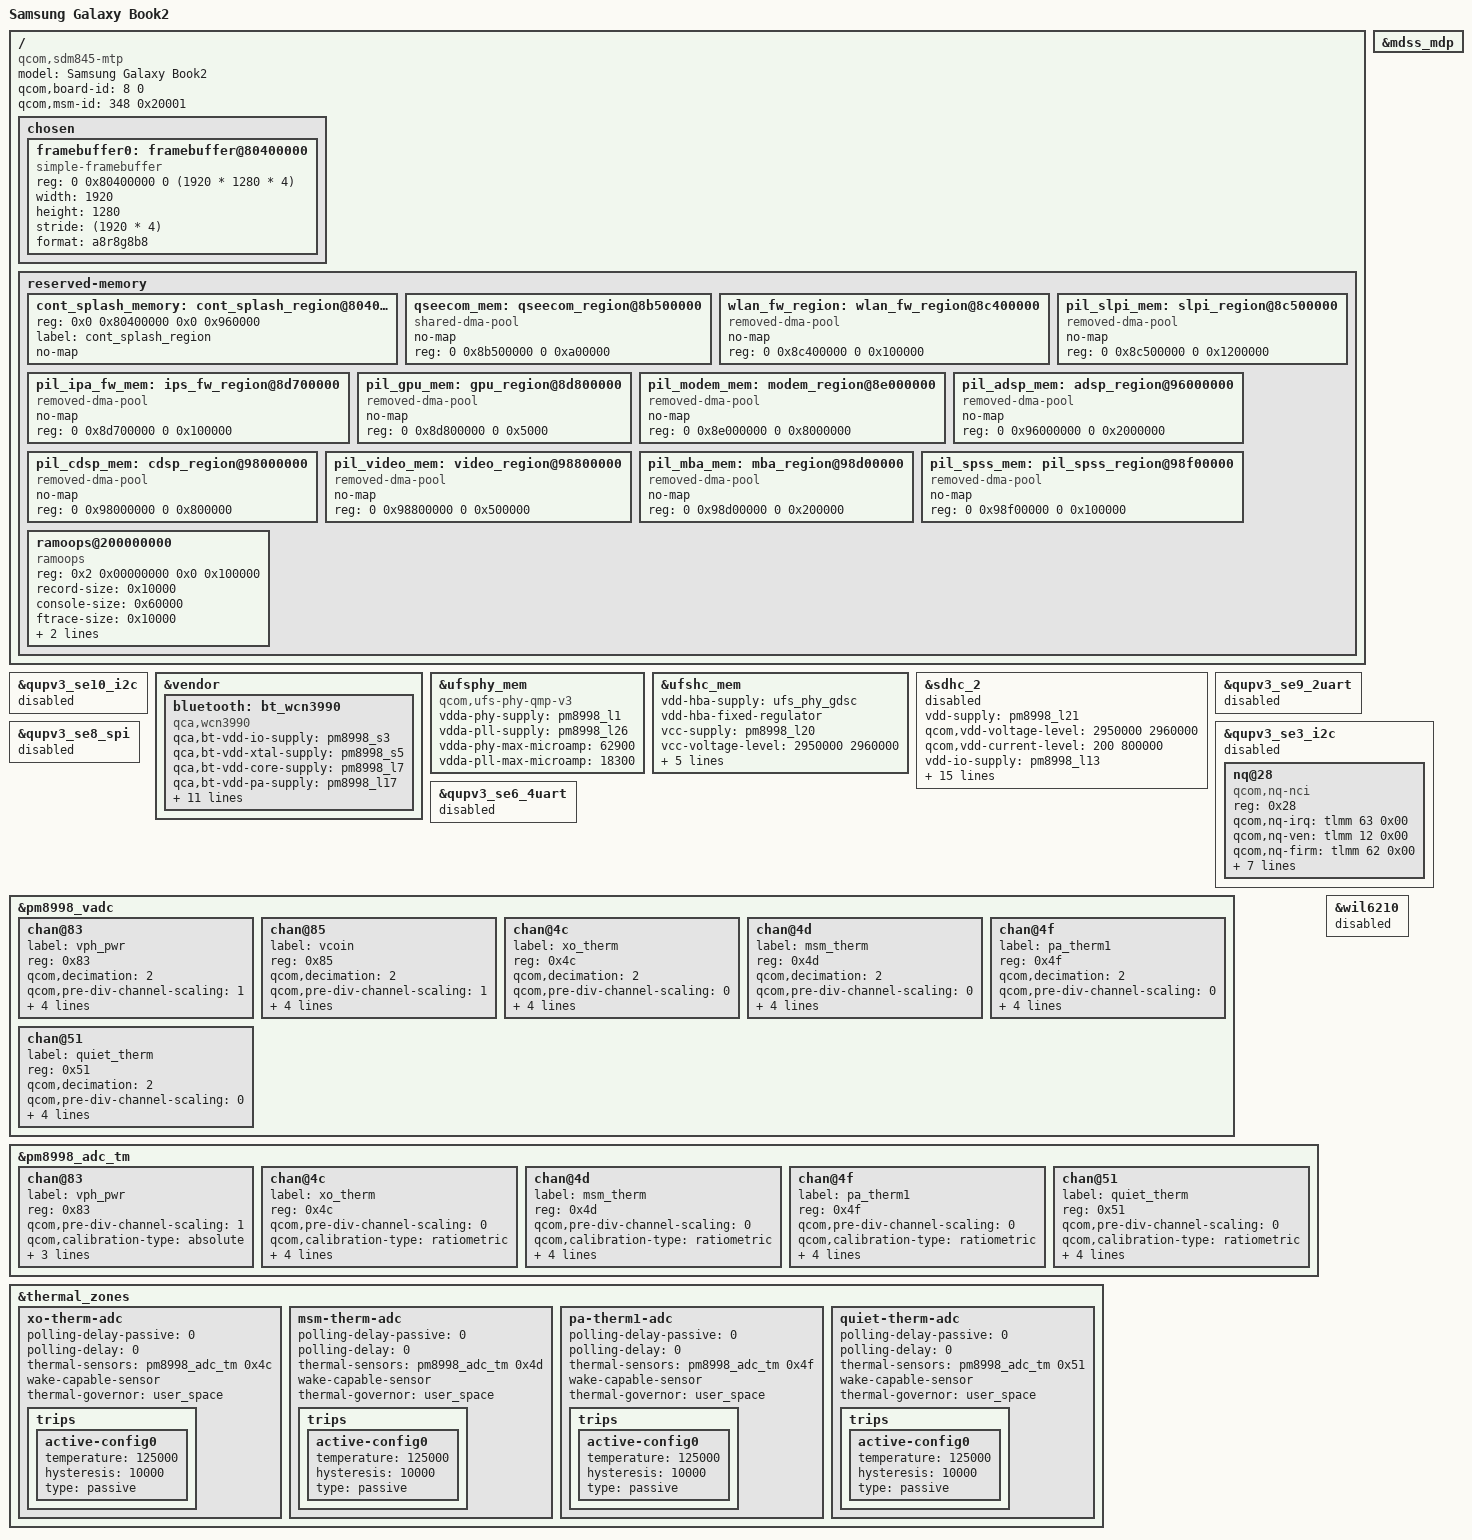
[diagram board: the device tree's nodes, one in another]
/dts-v1/;

#include "sdm845-v2.1.dtsi"
#include "sdm845-sde-display.dtsi"
#include <dt-bindings/gpio/gpio.h>
// #include "sdm845-pmic-overlay.dtsi"
// #include "sdm845-pinctrl-overlay.dtsi"
// #include "sdm845-camera-sensor-mtp.dtsi"

/delete-node/ &cont_splash_memory;
/delete-node/ &qseecom_mem;
/delete-node/ &wlan_fw_region;
/delete-node/ &pil_slpi_mem;
/delete-node/ &pil_ipa_fw_mem;
/delete-node/ &pil_ipa_gsi_mem;
/delete-node/ &pil_gpu_mem;
/delete-node/ &pil_modem_mem;
/delete-node/ &pil_adsp_mem;
/delete-node/ &pil_cdsp_mem;
/delete-node/ &pil_video_mem;
/delete-node/ &pil_mba_mem;
/delete-node/ &pil_spss_mem;

/ {
	model = "Samsung Galaxy Book2";
	compatible = "qcom,sdm845-mtp", "qcom,sdm845", "qcom,mtp";
	qcom,board-id = <8 0>;
    qcom,msm-id = <348 0x20001>;

	chosen {
		#address-cells = <2>;
		#size-cells = <2>;
		ranges;

		// Firmware initialized the display at 1280p instead of 1440p
		framebuffer0: framebuffer@80400000 {
			compatible = "simple-framebuffer";
			reg = <0 0x80400000 0 (1920 * 1280 * 4)>;
			width = <1920>;
			height = <1280>;
			stride = <(1920 * 4)>;
			format = "a8r8g8b8";
		};
	};

    reserved-memory {
        /* Bootloader display framebuffer region */
		cont_splash_memory: cont_splash_region@80400000 {
			reg = <0x0 0x80400000 0x0 0x960000>;
			label = "cont_splash_region";
            no-map;
		};

		qseecom_mem: qseecom_region@8b500000 {
			compatible = "shared-dma-pool";
			no-map;
			reg = <0 0x8b500000 0 0xa00000>;
		};

		wlan_fw_region: wlan_fw_region@8c400000 {
			compatible = "removed-dma-pool";
			no-map;
			reg = <0 0x8c400000 0 0x100000>;
		};

		pil_slpi_mem: slpi_region@8c500000 {
			compatible = "removed-dma-pool";
			no-map;
			reg = <0 0x8c500000 0 0x1200000>;
		};

		pil_ipa_fw_mem: ips_fw_region@8d700000 {
			compatible = "removed-dma-pool";
			no-map;
			reg = <0 0x8d700000 0 0x100000>;
		};

		pil_gpu_mem: gpu_region@8d800000 {
			compatible = "removed-dma-pool";
			no-map;
			reg = <0 0x8d800000 0 0x5000>;
		};

		pil_modem_mem: modem_region@8e000000 {
			compatible = "removed-dma-pool";
			no-map;
			reg = <0 0x8e000000 0 0x8000000>;
		};

		pil_adsp_mem: adsp_region@96000000 {
			compatible = "removed-dma-pool";
			no-map;
			reg = <0 0x96000000 0 0x2000000>;
		};

		pil_cdsp_mem: cdsp_region@98000000 {
			compatible = "removed-dma-pool";
			no-map;
			reg = <0 0x98000000 0 0x800000>;
		};

		pil_video_mem: video_region@98800000 {
			compatible = "removed-dma-pool";
			no-map;
			reg = <0 0x98800000 0 0x500000>;
		};

		pil_mba_mem: mba_region@98d00000 {
			compatible = "removed-dma-pool";
			no-map;
			reg = <0 0x98d00000 0 0x200000>;
		};

		pil_spss_mem: pil_spss_region@98f00000 {
			compatible = "removed-dma-pool";
			no-map;
			reg = <0 0x98f00000 0 0x100000>;
		};

		ramoops@200000000 {
			compatible = "ramoops";
			reg = <0x2 0x00000000 0x0 0x100000>;
			record-size = <0x10000>;
			console-size = <0x60000>;
			ftrace-size = <0x10000>;
			pmsg-size = <0x20000>;
			ecc-size = <0>;
		};
    };
};

&qupv3_se10_i2c {
// #include "smb1355.dtsi"
};

&vendor {
	bluetooth: bt_wcn3990 {
		compatible = "qca,wcn3990";
		qca,bt-vdd-io-supply = <&pm8998_s3>;
		qca,bt-vdd-xtal-supply = <&pm8998_s5>;
		qca,bt-vdd-core-supply = <&pm8998_l7>;
		qca,bt-vdd-pa-supply = <&pm8998_l17>;
		qca,bt-vdd-ldo-supply = <&pm8998_l25>;

		qca,bt-vdd-io-voltage-level = <1352000 1352000>;
		qca,bt-vdd-xtal-voltage-level = <2040000 2040000>;
		qca,bt-vdd-core-voltage-level = <1800000 1800000>;
		qca,bt-vdd-pa-voltage-level = <1304000 1304000>;
		qca,bt-vdd-ldo-voltage-level = <3312000 3312000>;

		qca,bt-vdd-io-current-level = <1>; /* LPM/PFM */
		qca,bt-vdd-xtal-current-level = <1>; /* LPM/PFM */
		qca,bt-vdd-core-current-level = <1>; /* LPM/PFM */
		qca,bt-vdd-pa-current-level = <1>; /* LPM/PFM */
		qca,bt-vdd-ldo-current-level = <1>; /* LPM/PFM */
	};
};

// &soc {
// 	gpio_keys {
// 		compatible = "gpio-keys";
// 		label = "gpio-keys";

// 		pinctrl-names = "default";
// 		pinctrl-0 = <&key_vol_up_default
// 			     &key_cam_snapshot_default
// 			     &key_cam_focus_default>;

// 		vol_up {
// 			label = "volume_up";
// 			gpios = <&pm8998_gpios 6 GPIO_ACTIVE_LOW>;
// 			linux,input-type = <1>;
// 			linux,code = <115>;
// 			gpio-key,wakeup;
// 			debounce-interval = <15>;
// 			linux,can-disable;
// 		};

// 		cam_snapshot {
// 			label = "cam_snapshot";
// 			gpios = <&pm8998_gpios 7 GPIO_ACTIVE_LOW>;
// 			linux,input-type = <1>;
// 			linux,code = <766>;
// 			gpio-key,wakeup;
// 			debounce-interval = <15>;
// 			linux,can-disable;
// 		};

// 		cam_focus {
// 			label = "cam_focus";
// 			gpios = <&pm8998_gpios 8 GPIO_ACTIVE_LOW>;
// 			linux,input-type = <1>;
// 			linux,code = <528>;
// 			gpio-key,wakeup;
// 			debounce-interval = <15>;
// 			linux,can-disable;
// 		};
// 	};
// };

// &labibb {
// 	status = "disabled";
// 	qcom,qpnp-labibb-mode = "lcd";
// };

// &pmi8998_wled {
// 	status = "disabled";
// 	qcom,led-strings-list = [01 02];
// };

// &pmi8998_haptics {
// 	qcom,vmax-mv = <2400>;
// 	qcom,lra-auto-mode;
// 	status = "disabled";
// };

&mdss_mdp {
	#cooling-cells = <2>;
};

&ufsphy_mem {
	compatible = "qcom,ufs-phy-qmp-v3";

	vdda-phy-supply = <&pm8998_l1>; /* 0.88v */
	vdda-pll-supply = <&pm8998_l26>; /* 1.2v */
	vdda-phy-max-microamp = <62900>;
	vdda-pll-max-microamp = <18300>;

	status = "ok";
};

&ufshc_mem {
	vdd-hba-supply = <&ufs_phy_gdsc>;
	vdd-hba-fixed-regulator;
	vcc-supply = <&pm8998_l20>;
	vcc-voltage-level = <2950000 2960000>;
	vccq2-supply = <&pm8998_s4>;
	vcc-max-microamp = <600000>;
	vccq2-max-microamp = <600000>;

	qcom,vddp-ref-clk-supply = <&pm8998_l2>;
	qcom,vddp-ref-clk-max-microamp = <100>;

	status = "ok";
};

&sdhc_2 {
	vdd-supply = <&pm8998_l21>;
	qcom,vdd-voltage-level = <2950000 2960000>;
	qcom,vdd-current-level = <200 800000>;

	vdd-io-supply = <&pm8998_l13>;
	qcom,vdd-io-voltage-level = <1808000 2960000>;
	qcom,vdd-io-current-level = <200 22000>;

	pinctrl-names = "active", "sleep", "ds_400KHz",
			"ds_50MHz", "ds_100MHz", "ds_200MHz";
	pinctrl-0 = <&sdc2_clk_on  &sdc2_cmd_on &sdc2_data_on &storage_cd>;
	pinctrl-1 = <&sdc2_clk_off &sdc2_cmd_off &sdc2_data_off &storage_cd>;
	pinctrl-2 = <&sdc2_clk_ds_400KHz
			&sdc2_cmd_ds_400KHz &sdc2_data_ds_400KHz>;
	pinctrl-3 = <&sdc2_clk_ds_50MHz
			&sdc2_cmd_ds_50MHz &sdc2_data_ds_50MHz>;
	pinctrl-4 = <&sdc2_clk_ds_100MHz
			&sdc2_cmd_ds_100MHz &sdc2_data_ds_100MHz>;
	pinctrl-5 = <&sdc2_clk_ds_200MHz
			&sdc2_cmd_ds_200MHz &sdc2_data_ds_200MHz>;

	cd-gpios = <&tlmm 126 GPIO_ACTIVE_LOW>;

	status = "disabled";
};

// &pmi8998_switch1 {
// 	pinctrl-names = "led_enable", "led_disable";
// 	pinctrl-0 = <&flash_led3_front_en>;
// 	pinctrl-1 = <&flash_led3_front_dis>;
// };

// &pmi8998_switch2 {
// 	pinctrl-names = "led_enable", "led_disable";
// 	pinctrl-0 = <&flash_led3_iris_en>;
// 	pinctrl-1 = <&flash_led3_iris_dis>;
// };

// &vendor {
// 	mtp_batterydata: qcom,battery-data {
// 		qcom,batt-id-range-pct = <15>;
// 		// #include "fg-gen3-batterydata-itech-3000mah.dtsi"
// 		// #include "fg-gen3-batterydata-ascent-3450mah.dtsi"
// 		// #include "fg-gen3-batterydata-demo-6000mah.dtsi"
// 	};

// 	extcon_usb1: extcon_usb1 {
// 		compatible = "linux,extcon-usb-gpio";
// 		vbus-gpio = <&pmi8998_gpios 8 GPIO_ACTIVE_HIGH>;

// 		pinctrl-names = "default";
// 		pinctrl-0 = <&usb2_vbus_det_default>;
// 	};
// };

// &pmi8998_fg {
// 	qcom,battery-data = <&mtp_batterydata>;
// };

// &smb1355_charger_0 {
// 	status = "disabled";
// 	qcom,disable-ctm;
// };

// &smb1355_charger_1 {
// 	status = "disabled";
// 	qcom,disable-ctm;
// };

&qupv3_se9_2uart {
	status = "disabled";
};

&qupv3_se8_spi {
	status = "disabled";
};

&qupv3_se3_i2c {
	status = "disabled";
	nq@28 {
		compatible = "qcom,nq-nci";
		reg = <0x28>;
		qcom,nq-irq = <&tlmm 63 0x00>;
		qcom,nq-ven = <&tlmm 12 0x00>;
		qcom,nq-firm = <&tlmm 62 0x00>;
		qcom,nq-clkreq = <&pm8998_gpios 21 0x00>;
		qcom,nq-esepwr = <&tlmm 116 0x00>;
		interrupt-parent = <&tlmm>;
		interrupts = <63 0>;
		interrupt-names = "nfc_irq";
		pinctrl-names = "nfc_active", "nfc_suspend";
		pinctrl-0 = <&nfc_int_active
			     &nfc_enable_active
			     &nfc_clk_default>;
		pinctrl-1 = <&nfc_int_suspend &nfc_enable_suspend>;
	};
};

&qupv3_se10_i2c {
	status = "disabled";
};

&qupv3_se6_4uart {
	status = "disabled";
};

// &usb1 {
// 	extcon = <&extcon_usb1>;
// };

// &ext_5v_boost {
// 	status = "disabled";
// };

&pm8998_vadc {
	chan@83 {
		label = "vph_pwr";
		reg = <0x83>;
		qcom,decimation = <2>;
		qcom,pre-div-channel-scaling = <1>;
		qcom,calibration-type = "absolute";
		qcom,scale-function = <0>;
		qcom,hw-settle-time = <0>;
		qcom,fast-avg-setup = <0>;
	};

	chan@85 {
		label = "vcoin";
		reg = <0x85>;
		qcom,decimation = <2>;
		qcom,pre-div-channel-scaling = <1>;
		qcom,calibration-type = "absolute";
		qcom,scale-function = <0>;
		qcom,hw-settle-time = <0>;
		qcom,fast-avg-setup = <0>;
	};

	chan@4c {
		label = "xo_therm";
		reg = <0x4c>;
		qcom,decimation = <2>;
		qcom,pre-div-channel-scaling = <0>;
		qcom,calibration-type = "ratiometric";
		qcom,scale-function = <4>;
		qcom,hw-settle-time = <2>;
		qcom,fast-avg-setup = <0>;
	};

	chan@4d {
		label = "msm_therm";
		reg = <0x4d>;
		qcom,decimation = <2>;
		qcom,pre-div-channel-scaling = <0>;
		qcom,calibration-type = "ratiometric";
		qcom,scale-function = <2>;
		qcom,hw-settle-time = <2>;
		qcom,fast-avg-setup = <0>;
	};

	chan@4f {
		label = "pa_therm1";
		reg = <0x4f>;
		qcom,decimation = <2>;
		qcom,pre-div-channel-scaling = <0>;
		qcom,calibration-type = "ratiometric";
		qcom,scale-function = <2>;
		qcom,hw-settle-time = <2>;
		qcom,fast-avg-setup = <0>;
	};

	chan@51 {
		label = "quiet_therm";
		reg = <0x51>;
		qcom,decimation = <2>;
		qcom,pre-div-channel-scaling = <0>;
		qcom,calibration-type = "ratiometric";
		qcom,scale-function = <2>;
		qcom,hw-settle-time = <2>;
		qcom,fast-avg-setup = <0>;
	};
};

&pm8998_adc_tm {
	chan@83 {
		label = "vph_pwr";
		reg = <0x83>;
		qcom,pre-div-channel-scaling = <1>;
		qcom,calibration-type = "absolute";
		qcom,scale-function = <0>;
		qcom,hw-settle-time = <0>;
		qcom,btm-channel-number = <0x60>;
	};

	chan@4c {
		label = "xo_therm";
		reg = <0x4c>;
		qcom,pre-div-channel-scaling = <0>;
		qcom,calibration-type = "ratiometric";
		qcom,scale-function = <4>;
		qcom,hw-settle-time = <2>;
		qcom,btm-channel-number = <0x68>;
		qcom,thermal-node;
	};

	chan@4d {
		label = "msm_therm";
		reg = <0x4d>;
		qcom,pre-div-channel-scaling = <0>;
		qcom,calibration-type = "ratiometric";
		qcom,scale-function = <2>;
		qcom,hw-settle-time = <2>;
		qcom,btm-channel-number = <0x70>;
		qcom,thermal-node;
	};

	chan@4f {
		label = "pa_therm1";
		reg = <0x4f>;
		qcom,pre-div-channel-scaling = <0>;
		qcom,calibration-type = "ratiometric";
		qcom,scale-function = <2>;
		qcom,hw-settle-time = <2>;
		qcom,btm-channel-number = <0x78>;
		qcom,thermal-node;
	};

	chan@51 {
		label = "quiet_therm";
		reg = <0x51>;
		qcom,pre-div-channel-scaling = <0>;
		qcom,calibration-type = "ratiometric";
		qcom,scale-function = <2>;
		qcom,hw-settle-time = <2>;
		qcom,btm-channel-number = <0x80>;
		qcom,thermal-node;
	};
};

&thermal_zones {
	xo-therm-adc {
		polling-delay-passive = <0>;
		polling-delay = <0>;
		thermal-sensors = <&pm8998_adc_tm 0x4c>;
		wake-capable-sensor;
		thermal-governor = "user_space";

		trips {
			active-config0 {
				temperature = <125000>;
				hysteresis = <10000>;
				type = "passive";
			};
		};
	};

	msm-therm-adc {
		polling-delay-passive = <0>;
		polling-delay = <0>;
		thermal-sensors = <&pm8998_adc_tm 0x4d>;
		wake-capable-sensor;
		thermal-governor = "user_space";

		trips {
			active-config0 {
				temperature = <125000>;
				hysteresis = <10000>;
				type = "passive";
			};
		};
	};

	pa-therm1-adc {
		polling-delay-passive = <0>;
		polling-delay = <0>;
		thermal-sensors = <&pm8998_adc_tm 0x4f>;
		wake-capable-sensor;
		thermal-governor = "user_space";

		trips {
			active-config0 {
				temperature = <125000>;
				hysteresis = <10000>;
				type = "passive";
			};
		};
	};

	quiet-therm-adc {
		polling-delay-passive = <0>;
		polling-delay = <0>;
		thermal-sensors = <&pm8998_adc_tm 0x51>;
		wake-capable-sensor;
		thermal-governor = "user_space";

		trips {
			active-config0 {
				temperature = <125000>;
				hysteresis = <10000>;
				type = "passive";
			};
		};
	};
};

&wil6210 {
	status = "disabled";
};
